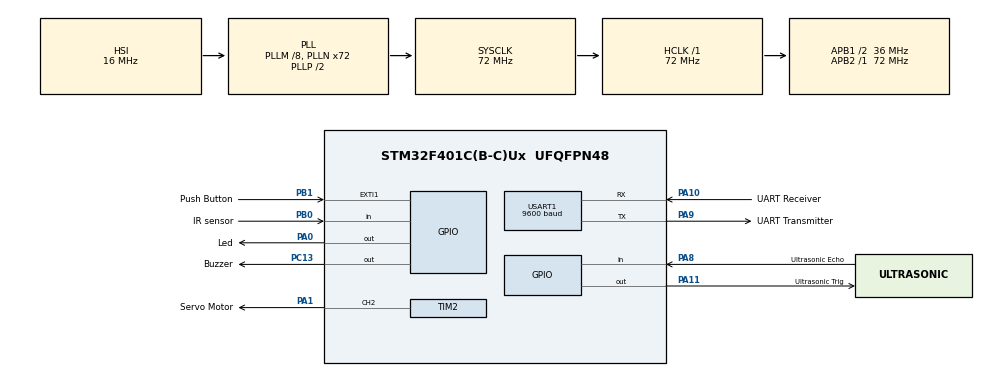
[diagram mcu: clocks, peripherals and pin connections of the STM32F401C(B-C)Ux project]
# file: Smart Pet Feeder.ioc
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Mcu.Family=STM32F4
Mcu.Name=STM32F401C(B-C)Ux
Mcu.Package=UFQFPN48
NVIC.EXTI1_IRQn=true\:0\:0\:false\:false\:true\:true\:true\:true
NVIC.PriorityGroup=NVIC_PRIORITYGROUP_4
NVIC.USART1_IRQn=true\:0\:0\:false\:false\:true\:true\:true\:true
PA0-WKUP.GPIO_Label=Led
PA0-WKUP.Signal=GPIO_Output
PA1.GPIO_Label=Servo Motor
PA1.Signal=S_TIM2_CH2
PA10.GPIO_Label=UART Receiver
PA10.Mode=Asynchronous
PA10.Signal=USART1_RX
PA11.GPIO_Label=Ultrasonic Trig
PA11.Signal=GPIO_Output
PA13.Mode=Serial_Wire
PA13.Signal=SYS_JTMS-SWDIO
PA14.Mode=Serial_Wire
PA14.Signal=SYS_JTCK-SWCLK
PA8.GPIO_Label=Ultrasonic Echo
PA8.Signal=GPIO_Input
PA9.GPIO_Label=UART Transmitter
PA9.Mode=Asynchronous
PA9.Signal=USART1_TX
PB0.GPIO_Label=IR sensor
PB0.Signal=GPIO_Input
PB1.GPIO_Label=Push Button
PB1.Signal=GPXTI1
PC13-ANTI_TAMP.GPIO_Label=Buzzer
PC13-ANTI_TAMP.Signal=GPIO_Output
PH0\ -\ OSC_IN.Mode=HSE-External-Oscillator
PH0\ -\ OSC_IN.Signal=RCC_OSC_IN
PH1\ -\ OSC_OUT.Mode=HSE-External-Oscillator
PH1\ -\ OSC_OUT.Signal=RCC_OSC_OUT
ProjectManager.HeapSize=0x200
ProjectManager.StackSize=0x400
ProjectManager.TargetToolchain=STM32CubeIDE
RCC.48MHZClocksFreq_Value=36000000
RCC.AHBFreq_Value=72000000
RCC.APB1CLKDivider=RCC_HCLK_DIV2
RCC.APB1Freq_Value=36000000
RCC.APB1TimFreq_Value=72000000
RCC.APB2Freq_Value=72000000
RCC.APB2TimFreq_Value=72000000
RCC.CortexFreq_Value=72000000
RCC.HCLKFreq_Value=72000000
RCC.HSE_VALUE=25000000
RCC.HSI_VALUE=16000000
RCC.LSE_VALUE=32768
RCC.PLLM=8
RCC.PLLN=72
RCC.SYSCLKFreq_VALUE=72000000
RCC.SYSCLKSource=RCC_SYSCLKSOURCE_PLLCLK
RCC.VCOOutputFreq_Value=144000000
SH.S_TIM2_CH2.0=TIM2_CH2,PWM Generation2 CH2
TIM1.Prescaler=71
TIM2.Channel-PWM\ Generation2\ CH2=TIM_CHANNEL_2
TIM2.Period=9999
TIM2.Prescaler=15
USART1.BaudRate=9600
USART1.VirtualMode=VM_ASYNC
VP_TIM1_VS_ClockSourceINT.Mode=Internal
board=custom

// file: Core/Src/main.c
#include "main.h"

TIM_HandleTypeDef htim1;
TIM_HandleTypeDef htim2;
UART_HandleTypeDef huart1;

/* USER CODE BEGIN PV */
#define TRIG_PIN GPIO_PIN_11
#define TRIG_PORT GPIOA
#define ECHO_PIN GPIO_PIN_8
#define ECHO_PORT GPIOA

// Global Variables Needed

uint8_t rxData;
uint8_t i =0;
uint16_t angle =2500;
uint32_t previousMillis = 0;
uint32_t currentMillis = 0;

uint16_t counterh=0;
uint16_t counterm=0;
uint16_t counterl=0;

uint32_t pMillis;
uint32_t Intial_time = 0;
uint32_t Final_time = 0;
uint16_t Distance  = 0;  // cm
uint16_t Capacity  = 0;

uint8_t data_Ultrasonic_Red[] = "*LR255G0B0*";
uint8_t data_Ultrasonic_Yellow[] = "*LR255G255B0*";
uint8_t data_Ultrasonic_Green[] = "*LR0G255B0*";
uint8_t data_IR_Green[] = "*VR0G255B0*";
uint8_t data_IR_Red[] = "*VR255G0B0*";

uint8_t dataHigh[] = "*KHigh*";
uint8_t dataMedium[] = "*KMedium*";
uint8_t dataLow[] = "*KLow*";
uint8_t datafull[] = "*TFull*";
uint8_t dataempty[] = "*TEmpty*";

uint8_t Servo_command = 0;
/* USER CODE END PV */

void SystemClock_Config(void);	//for Clock configuration
static void MX_GPIO_Init(void);	//GPIO initialization
static void MX_TIM1_Init(void);		//timer 1 initialization
static void MX_TIM2_Init(void);		//timer2 initialization
static void MX_USART1_UART_Init(void);		//usart1 initialization

int main(void)
{

  /* MCU Configuration--------------------------------------------------------*/

  /* Reset of all peripherals, Initializes the Flash interface and the Systick. */
  HAL_Init();

  /* Configure the system clock */
  SystemClock_Config();

  /* Initialize all configured peripherals */
  MX_GPIO_Init();
  MX_TIM1_Init();
  MX_TIM2_Init();
  MX_USART1_UART_Init();
  /* USER CODE BEGIN 2 */
  HAL_TIM_Base_Start(&htim1);							   // start timer 1 for
  HAL_GPIO_WritePin(TRIG_PORT, TRIG_PIN, GPIO_PIN_RESET);  // pull the TRIG pin low
  HAL_TIM_PWM_Start(&htim2, TIM_CHANNEL_2);                // start timer 2 for PWM channel
  /* USER CODE END 2 */

  while (1)
  {
	  /*
	     Checking if action happened or NOT
	     if Servo_command is set, so the pet or user pressed a button
	     otherwise the Servo_command is cleared
	  */
	  if(Servo_command==1)
	  {
			__HAL_TIM_SET_COMPARE(&htim2, TIM_CHANNEL_2, 7500); //Open Servo Motor
			HAL_Delay(600);  									//Delay until food drops
			for(angle=7500; angle>=2500; angle -=50)			//Close Servo Motor wisely
			{
				__HAL_TIM_SET_COMPARE(&htim2, TIM_CHANNEL_2, angle);
				HAL_Delay(1);
			}

			for (i=0;i<6;i++) 									//Toggling LED & Buzzer
			{
				HAL_GPIO_TogglePin(GPIOA, GPIO_PIN_0);		//pin A0 is toggled
				HAL_GPIO_TogglePin(GPIOC, GPIO_PIN_13);		//pin C13 is toggled
				HAL_Delay(80);
			}
			Servo_command = 0;	//Servo off, turn off after being on
	  }

	  __HAL_TIM_SET_COMPARE(&htim2, TIM_CHANNEL_2, 2500); // return servo to original location

	  // IR Sensor Part
	   /*
	   * If the sensor is reading 0, food exists
	   * otherwise, dish status is indicating low food quantity
	   */
	  if (HAL_GPIO_ReadPin(GPIOB, GPIO_PIN_0) == 0)	//if The level is High in the dish
	  {
		  HAL_UART_Transmit(&huart1, data_IR_Green, sizeof(data_IR_Green), 10);		//Green led on app
	  }
	  else
	  {
		  HAL_UART_Transmit(&huart1, data_IR_Red, sizeof(data_IR_Red), 10);		//Red is on when Low level
	  }

	  // Ultra-sonic Sensor Part
	  HAL_GPIO_WritePin(TRIG_PORT, TRIG_PIN, GPIO_PIN_SET);  // pull the TRIG pin HIGH
	  __HAL_TIM_SET_COUNTER(&htim1, 0);
	  while (__HAL_TIM_GET_COUNTER (&htim1) < 10);  // wait for 10 us
	  HAL_GPIO_WritePin(TRIG_PORT, TRIG_PIN, GPIO_PIN_RESET);  // pull the TRIG pin low

	  pMillis = HAL_GetTick(); // used this to avoid infinite while loop  (for timeout)
	  // Wait for the echo pin to go high
	  while (!(HAL_GPIO_ReadPin (ECHO_PORT, ECHO_PIN)) && pMillis + 10 >  HAL_GetTick());
	  Intial_time = __HAL_TIM_GET_COUNTER (&htim1);

      pMillis = HAL_GetTick(); // used this to avoid infinite while loop (for timeout)
	  // Wait for the echo pin to go low
      while ((HAL_GPIO_ReadPin (ECHO_PORT, ECHO_PIN)) && pMillis + 50 > HAL_GetTick());
      Final_time = __HAL_TIM_GET_COUNTER (&htim1);

      // Measuring Distance
      Distance = (Final_time-Intial_time)* 0.034/2;  //velocity of sound 0.034 cm/us

      // Cases of different distances

      // Counters created for preventing 1 or 2 error values from the ultrasonic sensor
     if(Distance >0 && Distance <= 10)		//if distance is between 0 and 10
        {
    	    counterh++;
    	    counterm=0;
    	    counterl=0;
    	    if(counterh >= 3)
    	    {
    	    	HAL_UART_Transmit(&huart1, data_Ultrasonic_Green, sizeof(data_Ultrasonic_Green), 10);
    	    	HAL_UART_Transmit(&huart1, dataHigh, sizeof(dataHigh), 10);
    	    }
		}
      else if (Distance > 10 && Distance <= 18)
		{
    	    counterh=0;
			counterm++;
			counterl=0;
			if (counterm >= 3)
			{
				HAL_UART_Transmit(&huart1, data_Ultrasonic_Yellow, sizeof(data_Ultrasonic_Yellow), 10);
				HAL_UART_Transmit(&huart1, dataMedium, sizeof(dataMedium), 10);
			}
		}
      else
      	{
    	   counterh=0;
    	   counterm=0;
    	   counterl++;
     	   if(counterl >= 3)
     	   {
     		   HAL_UART_Transmit(&huart1, data_Ultrasonic_Red, sizeof(data_Ultrasonic_Red), 10);
     		   HAL_UART_Transmit(&huart1, dataLow, sizeof(dataLow), 10);
     	   }
		}
	 HAL_UART_Receive_IT(&huart1,&rxData,1); // Enabling interrupt receive
  }
}

void SystemClock_Config(void)
{
  RCC_OscInitTypeDef RCC_OscInitStruct = {0};
  RCC_ClkInitTypeDef RCC_ClkInitStruct = {0};

  /** Configure the main internal regulator output voltage
  */
  __HAL_RCC_PWR_CLK_ENABLE();
  __HAL_PWR_VOLTAGESCALING_CONFIG(PWR_REGULATOR_VOLTAGE_SCALE2);

  /** Initializes the RCC Oscillators according to the specified parameters
  * in the RCC_OscInitTypeDef structure.
  */
  RCC_OscInitStruct.OscillatorType = RCC_OSCILLATORTYPE_HSI;
  RCC_OscInitStruct.HSIState = RCC_HSI_ON;
  RCC_OscInitStruct.HSICalibrationValue = RCC_HSICALIBRATION_DEFAULT;
  RCC_OscInitStruct.PLL.PLLState = RCC_PLL_ON;
  RCC_OscInitStruct.PLL.PLLSource = RCC_PLLSOURCE_HSI;
  RCC_OscInitStruct.PLL.PLLM = 8;
  RCC_OscInitStruct.PLL.PLLN = 72;
  RCC_OscInitStruct.PLL.PLLP = RCC_PLLP_DIV2;
  RCC_OscInitStruct.PLL.PLLQ = 4;
  if (HAL_RCC_OscConfig(&RCC_OscInitStruct) != HAL_OK)
  {
    Error_Handler();
  }

  /** Initializes the CPU, AHB and APB buses clocks
  */
  RCC_ClkInitStruct.ClockType = RCC_CLOCKTYPE_HCLK|RCC_CLOCKTYPE_SYSCLK
                              |RCC_CLOCKTYPE_PCLK1|RCC_CLOCKTYPE_PCLK2;
  RCC_ClkInitStruct.SYSCLKSource = RCC_SYSCLKSOURCE_PLLCLK;
  RCC_ClkInitStruct.AHBCLKDivider = RCC_SYSCLK_DIV1;
  RCC_ClkInitStruct.APB1CLKDivider = RCC_HCLK_DIV2;
  RCC_ClkInitStruct.APB2CLKDivider = RCC_HCLK_DIV1;

  if (HAL_RCC_ClockConfig(&RCC_ClkInitStruct, FLASH_LATENCY_2) != HAL_OK)
  {
    Error_Handler();
  }
}

static void MX_TIM1_Init(void)
{

  TIM_ClockConfigTypeDef sClockSourceConfig = {0};
  TIM_MasterConfigTypeDef sMasterConfig = {0};

  htim1.Instance = TIM1;
  htim1.Init.Prescaler = 71;
  htim1.Init.CounterMode = TIM_COUNTERMODE_UP;
  htim1.Init.Period = 65535;
  htim1.Init.ClockDivision = TIM_CLOCKDIVISION_DIV1;
  htim1.Init.RepetitionCounter = 0;
  htim1.Init.AutoReloadPreload = TIM_AUTORELOAD_PRELOAD_DISABLE;
  if (HAL_TIM_Base_Init(&htim1) != HAL_OK)
  {
    Error_Handler();
  }
  sClockSourceConfig.ClockSource = TIM_CLOCKSOURCE_INTERNAL;
  if (HAL_TIM_ConfigClockSource(&htim1, &sClockSourceConfig) != HAL_OK)
  {
    Error_Handler();
  }
  sMasterConfig.MasterOutputTrigger = TIM_TRGO_RESET;
  sMasterConfig.MasterSlaveMode = TIM_MASTERSLAVEMODE_DISABLE;
  if (HAL_TIMEx_MasterConfigSynchronization(&htim1, &sMasterConfig) != HAL_OK)
  {
    Error_Handler();
  }

}

static void MX_TIM2_Init(void)
{

  TIM_MasterConfigTypeDef sMasterConfig = {0};
  TIM_OC_InitTypeDef sConfigOC = {0};

  htim2.Instance = TIM2;
  htim2.Init.Prescaler = 15;
  htim2.Init.CounterMode = TIM_COUNTERMODE_UP;
  htim2.Init.Period = 9999;
  htim2.Init.ClockDivision = TIM_CLOCKDIVISION_DIV1;
  htim2.Init.AutoReloadPreload = TIM_AUTORELOAD_PRELOAD_DISABLE;
  if (HAL_TIM_PWM_Init(&htim2) != HAL_OK)
  {
    Error_Handler();
  }
  sMasterConfig.MasterOutputTrigger = TIM_TRGO_RESET;
  sMasterConfig.MasterSlaveMode = TIM_MASTERSLAVEMODE_DISABLE;
  if (HAL_TIMEx_MasterConfigSynchronization(&htim2, &sMasterConfig) != HAL_OK)
  {
    Error_Handler();
  }
  sConfigOC.OCMode = TIM_OCMODE_PWM1;
  sConfigOC.Pulse = 0;
  sConfigOC.OCPolarity = TIM_OCPOLARITY_HIGH;
  sConfigOC.OCFastMode = TIM_OCFAST_DISABLE;
  if (HAL_TIM_PWM_ConfigChannel(&htim2, &sConfigOC, TIM_CHANNEL_2) != HAL_OK)
  {
    Error_Handler();
  }
  HAL_TIM_MspPostInit(&htim2);

}

static void MX_USART1_UART_Init(void)
{

  huart1.Instance = USART1;
  huart1.Init.BaudRate = 9600;
  huart1.Init.WordLength = UART_WORDLENGTH_8B;
  huart1.Init.StopBits = UART_STOPBITS_1;
  huart1.Init.Parity = UART_PARITY_NONE;
  huart1.Init.Mode = UART_MODE_TX_RX;
  huart1.Init.HwFlowCtl = UART_HWCONTROL_NONE;
  huart1.Init.OverSampling = UART_OVERSAMPLING_16;
  if (HAL_UART_Init(&huart1) != HAL_OK)
  {
    Error_Handler();
  }

}

static void MX_GPIO_Init(void)
{
  GPIO_InitTypeDef GPIO_InitStruct = {0};

  /* GPIO Ports Clock Enable */
  __HAL_RCC_GPIOC_CLK_ENABLE();
  __HAL_RCC_GPIOH_CLK_ENABLE();
  __HAL_RCC_GPIOA_CLK_ENABLE();
  __HAL_RCC_GPIOB_CLK_ENABLE();

  /*Configure GPIO pin Output Level */
  HAL_GPIO_WritePin(Test_LED_GPIO_Port, Test_LED_Pin, GPIO_PIN_RESET);

  /*Configure GPIO pin Output Level */
  HAL_GPIO_WritePin(GPIOA, Led___Buzzer_Pin|Ultrasonic_Trig_Pin, GPIO_PIN_RESET);

  /*Configure GPIO pin : Buzzer_Pin */
  GPIO_InitStruct.Pin = Test_LED_Pin;
  GPIO_InitStruct.Mode = GPIO_MODE_OUTPUT_PP;
  GPIO_InitStruct.Pull = GPIO_NOPULL;
  GPIO_InitStruct.Speed = GPIO_SPEED_FREQ_LOW;
  HAL_GPIO_Init(Test_LED_GPIO_Port, &GPIO_InitStruct);

  /*Configure GPIO pins : Led__Pin Ultrasonic_Trig_Pin */
  GPIO_InitStruct.Pin = Led___Buzzer_Pin|Ultrasonic_Trig_Pin;
  GPIO_InitStruct.Mode = GPIO_MODE_OUTPUT_PP;
  GPIO_InitStruct.Pull = GPIO_NOPULL;
  GPIO_InitStruct.Speed = GPIO_SPEED_FREQ_LOW;
  HAL_GPIO_Init(GPIOA, &GPIO_InitStruct);

  /*Configure GPIO pin : IR_sensor_Pin */
  GPIO_InitStruct.Pin = IR_sensor_Pin;
  GPIO_InitStruct.Mode = GPIO_MODE_INPUT;
  GPIO_InitStruct.Pull = GPIO_NOPULL;
  HAL_GPIO_Init(IR_sensor_GPIO_Port, &GPIO_InitStruct);

  /*Configure GPIO pin : Push_Button_Pin */
  GPIO_InitStruct.Pin = Push_Button_Pin;
  GPIO_InitStruct.Mode = GPIO_MODE_IT_RISING;
  GPIO_InitStruct.Pull = GPIO_NOPULL;
  HAL_GPIO_Init(Push_Button_GPIO_Port, &GPIO_InitStruct);

  /*Configure GPIO pin : Ultrasonic_Echo_Pin */
  GPIO_InitStruct.Pin = Ultrasonic_Echo_Pin;
  GPIO_InitStruct.Mode = GPIO_MODE_INPUT;
  GPIO_InitStruct.Pull = GPIO_NOPULL;
  HAL_GPIO_Init(Ultrasonic_Echo_GPIO_Port, &GPIO_InitStruct);

  /* EXTI interrupt init*/
  HAL_NVIC_SetPriority(EXTI1_IRQn, 0, 0);
  HAL_NVIC_EnableIRQ(EXTI1_IRQn);

}

/* USER CODE BEGIN 4 */

// Push Button Interrupt

void HAL_GPIO_EXTI_Callback(uint16_t GPIO_Pin)
{
	currentMillis = HAL_GetTick();
	  if (GPIO_Pin == GPIO_PIN_1  								// button is pressed
			  && (currentMillis - previousMillis > 10)  		// Debouncing Effect condition
			  && HAL_GPIO_ReadPin(GPIOB, GPIO_PIN_0) == 1)		// IR is sensing No food
	  {
	    Servo_command = 1;
	    previousMillis = currentMillis;
	  }
}

// Mobile Application Interrupt

void HAL_UART_RxCpltCallback(UART_HandleTypeDef *huart)
{
  if(huart->Instance==USART1)
  {
    if(rxData== 'Y') // User pressed the (Add Food) button
    {
    	Servo_command = 1;
    }
    HAL_UART_Receive_IT(&huart1,&rxData,1); // Enabling interrupt receive again
  }
}

/* USER CODE END 4 */

void Error_Handler(void)
{
  __disable_irq();
  while (1)
  {
  }
}
